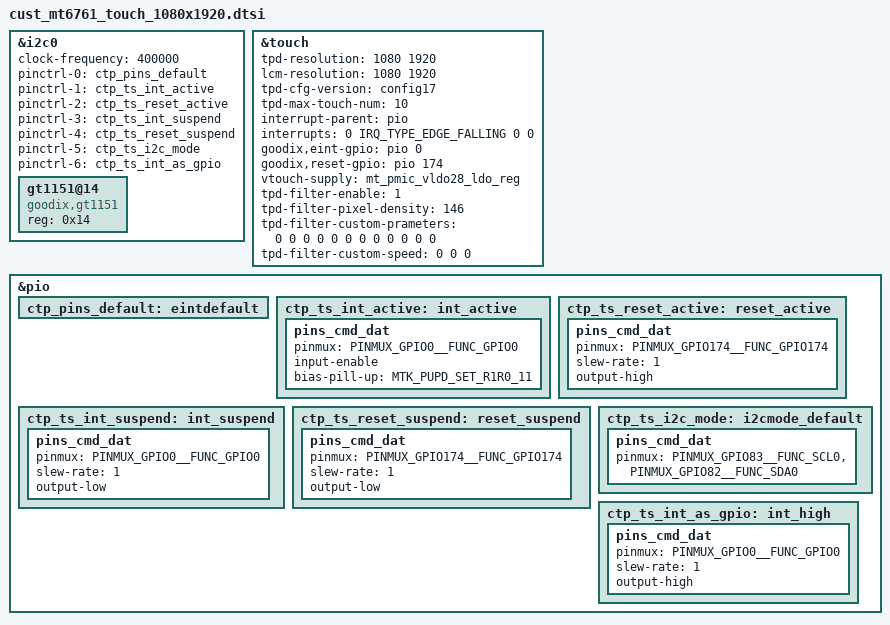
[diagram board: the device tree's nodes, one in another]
// SPDX-License-Identifier: GPL-2.0+
/*
 * Copyright (c) 2019 MediaTek Inc.
 *
 */

/* TOUCH start */
&i2c0 {
	clock-frequency = <400000>;
	pinctrl-names = "default", "ts_int_active",
		"ts_reset_active", "ts_int_suspend",
		"ts_reset_suspend", "ts_i2c_mode",
		"ts_eint_high";
	pinctrl-0 = <&ctp_pins_default>;
	pinctrl-1 = <&ctp_ts_int_active>;
	pinctrl-2 = <&ctp_ts_reset_active>;
	pinctrl-3 = <&ctp_ts_int_suspend>;
	pinctrl-4 = <&ctp_ts_reset_suspend>;
	pinctrl-5 = <&ctp_ts_i2c_mode>;
	pinctrl-6 = <&ctp_ts_int_as_gpio>;

	gt1151@14 {
		compatible = "goodix,gt1151";
		reg = <0x14>;
		status = "okay";
	};
};

&touch {
	tpd-resolution = <1080 1920>;
	lcm-resolution = <1080 1920>;
	tpd-cfg-version = "config17";
	tpd-max-touch-num = <10>;
	interrupt-parent = <&pio>;
	interrupts = <0 IRQ_TYPE_EDGE_FALLING 0 0>;
	goodix,eint-gpio = <&pio 0 0x0>;
	goodix,reset-gpio = <&pio 174 0x0>;
	vtouch-supply = <&mt_pmic_vldo28_ldo_reg>;

	/* Rotate cord when open blew lables */
	/*goodix,x2x;*/
	/*goodix,y2y;*/

	tpd-filter-enable = <1>;
	tpd-filter-pixel-density = <146>;
	tpd-filter-custom-prameters = <0 0 0 0 0 0 0 0 0 0 0 0>;
	tpd-filter-custom-speed = <0 0 0>;
	status = "okay";
};

&pio {
	ctp_pins_default: eintdefault {
	};
	ctp_ts_int_active: int_active {
		pins_cmd_dat {
			pinmux = <PINMUX_GPIO0__FUNC_GPIO0>;
			input-enable;
			bias-pill-up = <MTK_PUPD_SET_R1R0_11>;
		};
	};
	ctp_ts_reset_active: reset_active {
		pins_cmd_dat {
			pinmux = <PINMUX_GPIO174__FUNC_GPIO174>;
			slew-rate = <1>;
			output-high;
		};
	};
	ctp_ts_int_suspend: int_suspend {
		pins_cmd_dat {
			pinmux = <PINMUX_GPIO0__FUNC_GPIO0>;
			slew-rate = <1>;
			output-low;
		};
	};
	ctp_ts_reset_suspend: reset_suspend {
		pins_cmd_dat {
			pinmux = <PINMUX_GPIO174__FUNC_GPIO174>;
			slew-rate = <1>;
			output-low;
		};
	};
	ctp_ts_i2c_mode: i2cmode_default {
		pins_cmd_dat {
			pinmux = <PINMUX_GPIO83__FUNC_SCL0>,
				<PINMUX_GPIO82__FUNC_SDA0>;
		};
	};
	ctp_ts_int_as_gpio: int_high {
		pins_cmd_dat {
			pinmux = <PINMUX_GPIO0__FUNC_GPIO0>;
			slew-rate = <1>;
			output-high;
		};
	};
};
/* TOUCH end */
